# nrf5340_application register map
Vendor: Nordic Semiconductor; Series: nrf53; File version: 1
CPU: CM33 r0p4, little endian, MPU, FPU, 3 interrupt priority bits, 69 interrupts
Registers are 32-bit, read-write, reset 0x0 unless marked. A register's access mark holds for its fields unless they carry their own. Offsets are from the block's base; [hi:lo] are bit positions; lines under a group give offsets from that group; {n}, {i} and the like mark numbered series; 'fields as' and 'values as' point back to an identical list.

## FPU_NS — FPU control peripheral 0
Base 0x40000000; alternate view of DCNF_NS
Same registers: FPU_S 0x50000000 (alternate view of DCNF_S)
0x100 EVENTS_INVALIDOPERATION — An FPUIOC exception triggered by an invalid operation has occurred in the FPU
  [0] EVENTS_INVALIDOPERATION
    0=NotGenerated (Event not generated); 1=Generated (Event generated)
0x104 EVENTS_DIVIDEBYZERO — An FPUDZC exception triggered by a floating-point divide-by-zero operation has occurred in the FPU
  [0] EVENTS_DIVIDEBYZERO
    values as EVENTS_INVALIDOPERATION.EVENTS_INVALIDOPERATION
0x108 EVENTS_OVERFLOW — An FPUOFC exception triggered by a floating-point overflow has occurred in the FPU
  [0] EVENTS_OVERFLOW
    values as EVENTS_INVALIDOPERATION.EVENTS_INVALIDOPERATION
0x10C EVENTS_UNDERFLOW — An FPUUFC exception triggered by a floating-point underflow has occurred in the FPU
  [0] EVENTS_UNDERFLOW
    values as EVENTS_INVALIDOPERATION.EVENTS_INVALIDOPERATION
0x110 EVENTS_INEXACT — An FPUIXC exception triggered by an inexact floating-point operation has occurred in the FPU
  [0] EVENTS_INEXACT
    values as EVENTS_INVALIDOPERATION.EVENTS_INVALIDOPERATION
0x114 EVENTS_DENORMALINPUT — An FPUIDC exception triggered by a denormal floating-point input has occurred in the FPU
  [0] EVENTS_DENORMALINPUT
    values as EVENTS_INVALIDOPERATION.EVENTS_INVALIDOPERATION
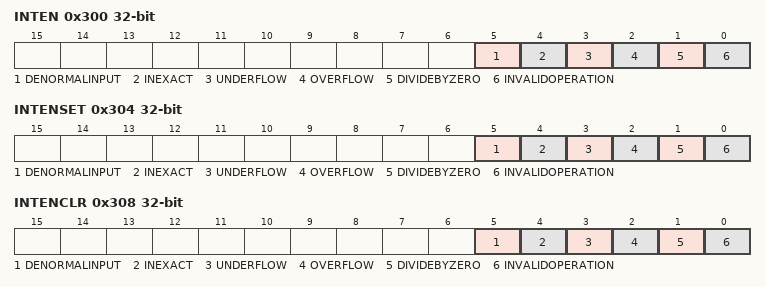
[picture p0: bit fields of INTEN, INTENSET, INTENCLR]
0x300 INTEN — Enable or disable interrupt
  [all] fields
    0=Disabled; 1=Enabled
  [5] DENORMALINPUT — Enable or disable interrupt for event DENORMALINPUT
  [4] INEXACT — Enable or disable interrupt for event INEXACT
  [3] UNDERFLOW — Enable or disable interrupt for event UNDERFLOW
  [2] OVERFLOW — Enable or disable interrupt for event OVERFLOW
  [1] DIVIDEBYZERO — Enable or disable interrupt for event DIVIDEBYZERO
  [0] INVALIDOPERATION — Enable or disable interrupt for event INVALIDOPERATION
0x304 INTENSET — Enable interrupt
  [all] fields
    on read: 0=Disabled (Read: Disabled); 1=Enabled (Read: Enabled) | on write: 1=Set (Enable)
  [5] DENORMALINPUT — Write '1' to enable interrupt for event DENORMALINPUT
  [4] INEXACT — Write '1' to enable interrupt for event INEXACT
  [3] UNDERFLOW — Write '1' to enable interrupt for event UNDERFLOW
  [2] OVERFLOW — Write '1' to enable interrupt for event OVERFLOW
  [1] DIVIDEBYZERO — Write '1' to enable interrupt for event DIVIDEBYZERO
  [0] INVALIDOPERATION — Write '1' to enable interrupt for event INVALIDOPERATION
0x308 INTENCLR — Disable interrupt
  [all] fields
    on read: 0=Disabled (Read: Disabled); 1=Enabled (Read: Enabled) | on write: 1=Clear (Disable)
  [5] DENORMALINPUT — Write '1' to disable interrupt for event DENORMALINPUT
  [4] INEXACT — Write '1' to disable interrupt for event INEXACT
  [3] UNDERFLOW — Write '1' to disable interrupt for event UNDERFLOW
  [2] OVERFLOW — Write '1' to disable interrupt for event OVERFLOW
  [1] DIVIDEBYZERO — Write '1' to disable interrupt for event DIVIDEBYZERO
  [0] INVALIDOPERATION — Write '1' to disable interrupt for event INVALIDOPERATION

## CACHE_S — Cache
Base 0x50001000
{0x400+0x20*i} PROFILING[{i}] (i=0..1) group — Unspecified
  0x00 IHIT ro — Description cluster: Instruction fetch cache hit counter for cache region n, where n=0 means Flash and n=1 means XIP.
    [31:0] HITS — Number of instruction cache hits
  0x04 IMISS ro — Description cluster: Instruction fetch cache miss counter for cache region n, where n=0 means Flash and n=1 means XIP.
    [31:0] MISSES — Number of instruction cache misses
  0x08 DHIT ro — Description cluster: Data fetch cache hit counter for cache region n, where n=0 means Flash and n=1 means XIP.
    [31:0] HITS — Number of data cache hits
  0x0C DMISS ro — Description cluster: Data fetch cache miss counter for cache region n, where n=0 means Flash and n=1 means XIP.
    [31:0] MISSES — Number of data cache misses
0x500 ENABLE — Enable cache.
  [0] ENABLE — Enable cache
    0=Disabled (Disable cache); 1=Enabled (Enable cache)
0x504 INVALIDATE wo — Invalidate the cache.
  [0] INVALIDATE — Invalidate the cache
    1=Invalidate the cache
0x508 ERASE wo — Erase the cache.
  [0] ERASE — Erase the cache
    1=Erase cache
0x50C PROFILINGENABLE — Enable the profiling counters.
  [0] ENABLE — Enable the profiling counters
    0=Disable profiling; 1=Enable profiling
0x510 PROFILINGCLEAR wo — Clear the profiling counters.
  [0] CLEAR — Clearing the profiling counters
    1=Clear the profiling counters
0x514 MODE — Cache mode. Switching from Cache to Ram mode causes the RAM to be cleared. Switching from RAM to Cache mode causes the cache to be invalidated.
  [0] MODE — Cache mode
    0=Cache mode; 1=Ram (RAM mode)
0x518 DEBUGLOCK rw-once — Lock debug mode.
  [0] DEBUGLOCK — Lock debug mode
    0=Unlocked (Debug mode unlocked); 1=Locked (Debug mode locked)
0x51C ERASESTATUS — Cache erase status.
  [0] ERASESTATUS — Cache erase status
    0=Idle (Erase is not complete or hasn't started); 1=Finished (Cache erase is finished)
0x520 WRITELOCK — Lock cache updates. Prevents updating of cache content on cache misses, but will continue to lookup instruction/data fetches in content already present in the cache. Ignored in RAM mode.
  [0] WRITELOCK — Lock cache updates
    0=Unlocked (Cache updates unlocked); 1=Locked (Cache updates locked)
